# ADuCM410 register map
Vendor: Analog Devices; Series: ADuCM410; File version: 1p0
ARM Cortex-CM33 Microcontroller based device
CPU: CM33 r0p1, little endian, MPU, FPU, 3 interrupt priority bits
Registers are 32-bit, read-write, reset 0x0 unless marked. A register's access mark holds for its fields unless they carry their own. Offsets are from the block's base; lines under a group give offsets from that group; [hi:lo] are bit positions; {n}, {i} and the like mark numbered series; 'fields as' and 'values as' point back to an identical list; <NAME> marks a mode.

## Memory map
0x40000000 GPT0 size 0x40
0x40000400 GPT1 size 0x40
0x40000800 GPT2 size 0x40
0x40000C00 GPTH0 size 0x100
0x40001000 GPTH1 size 0x100
0x40002000 MISC16 size 0x1000
0x40003000 WUT size 0x80
0x40004000 WDT size 0x100
0x40005000 ALLON size 0x80
0x40006000 PLA size 0x100
0x40007000 DMAREQ size 0x100
0x40020000 UART0 size 0x100
0x40020400 UART1 size 0x100
0x40020800 I2C0 size 0x80 — Some Description.
0x40020C00 I2C1 size 0x80
0x40021000 I2C2 size 0x80
0x40022000 MDIO size 0x40
0x40024000 D2D0 size 0x100 — Serial Peripheral Interface
0x40028000 D2D1 size 0x100
0x40040000 DMA size 0x1000
0x40044000 CACHE size 0x100 — Cache Controller
0x40048000 FLASH size 0x100
0x40050000 GPIO size 0x1000
0x40054000 SPI0 size 0x100
0x40058000 SPI1 size 0x100
0x4005C000 SPI2 size 0x100
0x40060000 CLK size 0x400
0x40064000 PWM size 0x80
0x40065000 SRAM size 0x1000
0x40066000 CRC size 0x100
0x40068000 ADC size 0x800
0x40068A00 COMP size 0x200
0x40069000 PGA size 0x200
0x40069200 PLL size 0x200
0x40069600 TMPSNS size 0x200
0x40069800 VDAC size 0x200

## Interrupts
0 WUT
11 WDT
12 GPT0
13 GPT1
14 GPT2
15 GPT3 (GPTH0)
16 GPT4 (GPTH1)
17 MDIO
18 FLASH
19 UART0
20 UART1
21 SPI0
22 SPI1
23 SPI2
24 I2C0S (I2C0)
25 I2C0M (I2C0)
26 I2C1S (I2C1)
27 I2C1M (I2C1)
28 I2C2S (I2C2)
29 I2C2M (I2C2)
30 PLA0 (PLA)
31 PLA1 (PLA)
32 PLA2 (PLA)
33 PLA3 (PLA)
34 PWM_TRIP (PWM)
35 PWM0 (PWM)
36 PWM1 (PWM)
37 PWM2 (PWM)
38 PWM3 (PWM)
39 SRAM_ERR (SRAM)
40 DMA_ERR (DMA)
41 DMA_SPI0_TX (DMA)
42 DMA_SPI0_RX (DMA)
43 DMA_SPI1_TX (DMA)
44 DMA_SPI1_RX (DMA)
45 DMA_SPI2_TX (DMA)
46 DMA_SPI2_RX (DMA)
47 DMA_UART0_TX (DMA)
48 DMA_UART0_RX (DMA)
49 DMA_UART1_TX (DMA)
50 DMA_UART1_RX (DMA)
51 DMA_I2C0S_TX (DMA)
52 DMA_I2C0S_RX (DMA)
53 DMA_I2C0M (DMA)
54 DMA_I2C1S_TX (DMA)
55 DMA_I2C1S_RX (DMA)
56 DMA_I2C1M (DMA)
57 DMA_I2C2S_TX (DMA)
58 DMA_I2C2S_RX (DMA)
59 DMA_I2C2M (DMA)
60 DMA_MDIO_TX (DMA)
61 DMA_MDIO_RX (DMA)
62 DMA_FLASH (DMA)
63 DMA_ADC (DMA)
64 PLL
66 ADC
67 SEQ (ADC)
68 COMP0 (COMP)
69 COMP1 (COMP)
70 COMP2 (COMP)
71 COMP3 (COMP)
72 VDAC
75 LVD2D (D2D0)
76 HVD2D (D2D1)
77 DMA_SPI_LV_TX (DMA)
78 DMA_SPI_LV_RX (DMA)
79 DMA_SPI_HV_TX (DMA)
80 DMA_SPI_HV_RX (DMA)
81 DMA_TRIG0 (DMA)
82 DMA_TRIG1 (DMA)
83 DMA_SW0 (DMA)
84 DMA_SW1 (DMA)
85 CACHE
86 DIG_COMP (ADC)
87 GPIO_INTA (GPIO)
88 GPIO_INTB (GPIO)

## GPT0
Base 0x40000000
Same registers: GPT1 0x40000400, GPT2 0x40000800
0x00 LD — 16-bit Load Value Register
  [15:0] LOAD range 0x00000000..0x0000FFFF — Load Value
0x04 VAL — 16-bit Timer Value Register
  [15:0] COUNT_VAL ro — Current Count
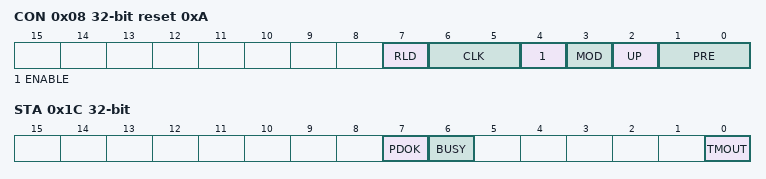
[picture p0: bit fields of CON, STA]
0x08 CON reset 0xA — Control Register
  [7] RLD — Reload Control
    0=DIS (Up/Down Counter is Only Reset on a Timeout Event); 1=EN (Resets the Up/down Counter When GPTCLRI[0] is Set)
  [6:5] CLK — Clock Select
    0=PCLK0; 1=HCLK (ROOT_CLK); 2=LFOSC (LFOSC. 32 KHz OSC); 3=HFXTAL (HFXTAL. 16 MHz OSC or XTAL (Dependent on CLKCON0.11))
  [4] ENABLE — Timer Enable
    0=DIS (DIS. Timer is Disabled (default)); 1=EN (EN. Timer is Enabled)
  [3] MOD — Timer Mode
    0=FREERUN (FREERUN.Timer Runs in Free Running Mode); 1=PERIODIC (PERIODIC. Timer Runs in Periodic Mode (default))
  [2] UP — Count up
    0=DIS (DIS. Timer is Set to Count Down (default)); 1=EN (EN. Timer is Set to Count up)
  [1:0] PRE — Prescaler
    0=DIV1OR4 (Source_clock / [1 or 4]); 1=DIV16 (Source_clock / 16); 2=DIV256 (Source_clock / 256); 3=DIV32768 (Source_clock / 32,768)
0x0C CLRI — Clear Interrupt Register
  [0] TMOUT range 0x00000000..0x00000001 — Clear Timeout Interrupt
0x1C STA — Status Register
  [7] PDOK ro — GPTCLRI Synchronization
    0=CLR_FLAG (CLR. the Interrupt is Cleared in the Timer Clock Domain); 1=SET_FLAG (SET. GPTCLRI[0] is Being Updated in the Timer Clock Domain)
  [6] BUSY ro — Timer Busy
    0=CLR_FLAG (Timer Ready to Receive Commands to GPTCON); 1=SET_FLAG (Timer Not Ready to Receive Commands to GPTCON)
  [0] TMOUT ro — Timeout Event Occurred
    0=CLR_FLAG (No Timeout Event Has Occurred); 1=SET_FLAG (a Timeout Event Has Occurred)

## Licence text in the file
ARM Limited (ARM) is supplying this software for use with Cortex-M processor based microcontroller, but can be equally used for other suitable processor architectures. This file can be freely distributed. Modifications to this file shall be clearly marked. THIS SOFTWARE IS PROVIDED "AS IS". NO WARRANTIES, WHETHER EXPRESS, IMPLIED OR STATUTORY, INCLUDING, BUT NOT LIMITED TO, IMPLIED WARRANTIES OF MERCHANTABILITY AND FITNESS FOR A PARTICULAR PURPOSE APPLY TO THIS SOFTWARE. ARM SHALL NOT, IN ANY CIRCUMSTANCES, BE LIABLE FOR SPECIAL, INCIDENTAL, OR CONSEQUENTIAL DAMAGES, FOR ANY REASON WHATSOEVER.

## Notices in the file
Copyright (c) 2020 Analog Devices, Inc.  All Rights Reserved.
This software is proprietary and confidential to Analog Devices, Inc.
and its licensors.
